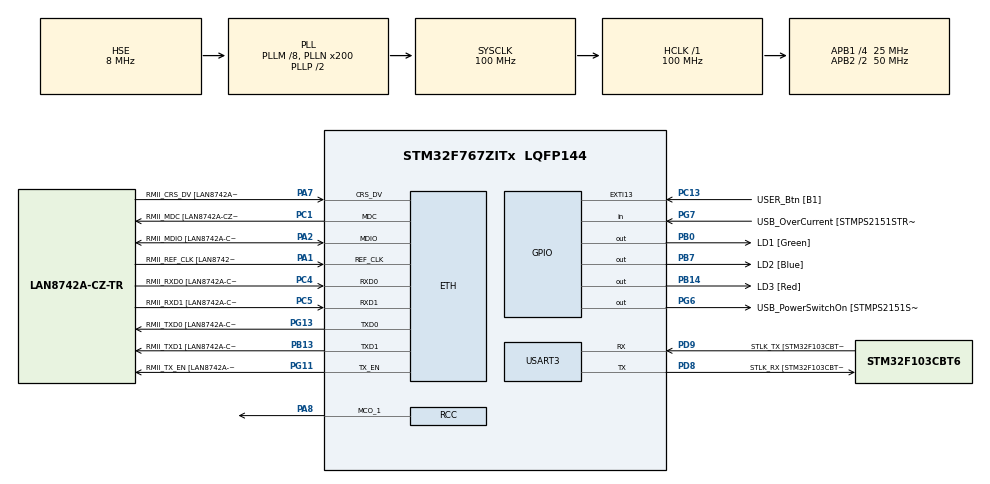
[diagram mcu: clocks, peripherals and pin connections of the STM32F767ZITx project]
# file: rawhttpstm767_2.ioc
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Mcu.Family=STM32F7
RCC.CortexFreq_Value=100000000
PG6.Signal=GPIO_Output
PB14.GPIO_Label=LD3 [Red]
PG6.GPIO_Label=USB_PowerSwitchOn [STMPS2151STR_EN]
PA14.GPIO_Label=TCK
RCC.SYSCLKSourceVirtual=RCC_SYSCLKSOURCE_PLLCLK
PB0.GPIO_Label=LD1 [Green]
PC14/OSC32_IN.Mode=LSE-External-Oscillator
PC5.Mode=RMII
PC13.GPIO_Label=USER_Btn [B1]
PB13.GPIO_Label=RMII_TXD1 [LAN8742A-CZ-TR_TXD1]
PB13.Signal=ETH_TXD1
PG13.Signal=ETH_TXD0
PD9.Mode=Asynchronous
PG11.Signal=ETH_TX_EN
RCC.SYSCLKSource=RCC_SYSCLKSOURCE_PLLCLK
ProjectManager.StackSize=0x400
LWIP.NETMASK_ADDRESS=255.255.000.000
LWIP.LWIP_HTTPD=1
USART3.VirtualMode-Asynchronous=VM_ASYNC
PA12.Signal=USB_OTG_FS_DP
ETH.PHY_Value=0
PH0/OSC_IN.Mode=HSE-External-Oscillator
RCC.HCLKFreq_Value=100000000
RCC.APB2TimFreq_Value=100000000
PH1/OSC_OUT.Signal=RCC_OSC_OUT
PD8.Signal=USART3_TX
RCC.AHBFreq_Value=100000000
RCC.HSE_VALUE=8000000
RCC.PLLMUL=RCC_PLL_MUL9
RCC.RCC_MCO1Source=RCC_MCO1SOURCE_PLLCLK
PC4.GPIO_Label=RMII_RXD0 [LAN8742A-CZ-TR_RXD0]
PA14.Mode=Serial_Wire
PA10.GPIO_Label=USB_ID
RCC.RCC_MCODiv1=RCC_MCODIV_4
PB7.Signal=GPIO_Output
PA8.Signal=RCC_MCO_1
PG13.Mode=RMII
ETH.PHY_Name=LAN8742A_PHY_ADDRESS
PH1/OSC_OUT.Mode=HSE-External-Oscillator
PB7.GPIO_Label=LD2 [Blue]
Mcu.Package=LQFP144
PC14/OSC32_IN.Signal=RCC_OSC32_IN
PA2.GPIO_Label=RMII_MDIO [LAN8742A-CZ-TR_MDIO]
PA10.Signal=USB_OTG_FS_ID
RCC.APB2CLKDivider=RCC_HCLK_DIV2
RCC.APB1TimFreq_Value=50000000
PG11.GPIO_Label=RMII_TX_EN [LAN8742A-CZ-TR_TXEN]
PC5.Signal=ETH_RXD1
PB13.Mode=RMII
PC4.Mode=RMII
LWIP.IP_ADDRESS=169.254.215.173
PB3.GPIO_Label=SWO
RCC.PLLSourceVirtual=RCC_PLLSOURCE_HSE
CORTEX_M7.CPU_ICache=Enabled
PA7.Mode=RMII
PG7.Signal=GPIO_Input
PD9.GPIO_Label=STLK_TX [STM32F103CBT6_PA2]
PC13.Signal=GPXTI13
PA9.GPIO_Label=USB_VBUS
PC4.Signal=ETH_RXD0
ETH.MACAddr=00\:80\:E1\:00\:00\:22
PA11.GPIO_Label=USB_DM
PD9.Signal=USART3_RX
LWIP.LWIP_DHCP=0
RCC.APB1CLKDivider=RCC_HCLK_DIV4
PG13.GPIO_Label=RMII_TXD0 [LAN8742A-CZ-TR_TXD0]
ETH.PhyAddress=0
PA12.GPIO_Label=USB_DP
VP_LWIP_VS_Enabled.Mode=Enabled
PD8.GPIO_Label=STLK_RX [STM32F103CBT6_PA3]
PA13.Signal=SYS_JTMS-SWDIO
CORTEX_M7.MPU_Control=MPU_HFNMI_PRIVDEF
ProjectManager.TargetToolchain=TrueSTUDIO
PA9.Signal=USB_OTG_FS_VBUS
RCC.USBFreq_Value=25000000
PD8.Mode=Asynchronous
PA1.Signal=ETH_REF_CLK
PB14.Signal=GPIO_Output
board=NUCLEO-F767ZI
RCC.VCOOutputFreq_Value=200000000
PH0/OSC_IN.Signal=RCC_OSC_IN
RCC.APB2Freq_Value=50000000
PA1.Mode=RMII
RCC.PRESCALERUSB=RCC_USBCLKSOURCE_PLL_DIV1_5
PG7.GPIO_Label=USB_OverCurrent [STMPS2151STR_FAULT]
PA1.GPIO_Label=RMII_REF_CLK [LAN8742A-CZ-TR_REFCLK0]
PC1.GPIO_Label=RMII_MDC [LAN8742A-CZ-TR_MDC]
PA13.Mode=Serial_Wire
Mcu.Name=STM32F767ZITx
PA2.Signal=ETH_MDIO
PA13.GPIO_Label=TMS
RCC.48MHZClocksFreq_Value=24000000
PB3.Signal=SYS_JTDO-SWO
RCC.SYSCLKFreq_VALUE=100000000
ETH.MediaInterface=ETH_MEDIA_INTERFACE_RMII
PA7.GPIO_Label=RMII_CRS_DV [LAN8742A-CZ-TR_CRS_DV]
PC5.GPIO_Label=RMII_RXD1 [LAN8742A-CZ-TR_RXD1]
PC15/OSC32_OUT.Mode=LSE-External-Oscillator
PG11.Mode=RMII
PA11.Signal=USB_OTG_FS_DM
PA14.Signal=SYS_JTCK-SWCLK
ProjectManager.HeapSize=0x200
LWIP.Version=v2.1.2_Cube
RCC.HSI_VALUE=16000000
PH0/OSC_IN.GPIO_Label=MCO [STM32F103CBT6_PA8]
RCC.PLLQ=8
NVIC.PriorityGroup=NVIC_PRIORITYGROUP_4
RCC.PLLM=8
RCC.PLLN=200
PA2.Mode=RMII
PC15/OSC32_OUT.Signal=RCC_OSC32_OUT
PA8.Mode=Clock-out-1
CORTEX_M7.CPU_DCache=Enabled
RCC.APB1Freq_Value=25000000
PB0.Signal=GPIO_Output
PC1.Signal=ETH_MDC
PC1.Mode=RMII
PA7.Signal=ETH_CRS_DV

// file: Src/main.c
/* USER CODE BEGIN Header */
/**
  ******************************************************************************
  * @file           : main.c
  * @brief          : Main program body
  ******************************************************************************
  * @attention
  *
  * <h2><center>&copy; Copyright (c) 2021 STMicroelectronics.
  * All rights reserved.</center></h2>
  *
  * This software component is licensed by ST under Ultimate Liberty license
  * SLA0044, the "License"; You may not use this file except in compliance with
  * the License. You may obtain a copy of the License at:
  *                             www.st.com/SLA0044
  *
  ******************************************************************************
  */
/* USER CODE END Header */

#include "main.h"
#include "lwip.h"

UART_HandleTypeDef huart3;

void SystemClock_Config(void);
static void MPU_Config(void);
static void MX_GPIO_Init(void);
static void MX_USART3_UART_Init(void);

int main(void)
{

  /* MPU Configuration--------------------------------------------------------*/
  MPU_Config();

  /* Enable I-Cache---------------------------------------------------------*/
  SCB_EnableICache();

  /* Enable D-Cache---------------------------------------------------------*/
  SCB_EnableDCache();

  /* MCU Configuration--------------------------------------------------------*/

  /* Reset of all peripherals, Initializes the Flash interface and the Systick. */
  HAL_Init();

  /* Configure the system clock */
  SystemClock_Config();

  /* Initialize all configured peripherals */
  MX_GPIO_Init();
  MX_USART3_UART_Init();
  MX_LWIP_Init();
  /* USER CODE BEGIN 2 */
  httpd_init();

  /* USER CODE END 2 */

  /* Infinite loop */
  /* USER CODE BEGIN WHILE */
  while (1)
  {
	  MX_LWIP_Process();
	  HAL_Delay(1);
    /* USER CODE END WHILE */

  }
}

void SystemClock_Config(void)
{
  RCC_OscInitTypeDef RCC_OscInitStruct = {0};
  RCC_ClkInitTypeDef RCC_ClkInitStruct = {0};
  RCC_PeriphCLKInitTypeDef PeriphClkInitStruct = {0};

  /** Configure LSE Drive Capability
  */
  HAL_PWR_EnableBkUpAccess();
  /** Configure the main internal regulator output voltage
  */
  __HAL_RCC_PWR_CLK_ENABLE();
  __HAL_PWR_VOLTAGESCALING_CONFIG(PWR_REGULATOR_VOLTAGE_SCALE3);
  /** Initializes the CPU, AHB and APB busses clocks
  */
  RCC_OscInitStruct.OscillatorType = RCC_OSCILLATORTYPE_HSE;
  RCC_OscInitStruct.HSEState = RCC_HSE_ON;
  RCC_OscInitStruct.PLL.PLLState = RCC_PLL_ON;
  RCC_OscInitStruct.PLL.PLLSource = RCC_PLLSOURCE_HSE;
  RCC_OscInitStruct.PLL.PLLM = 8;
  RCC_OscInitStruct.PLL.PLLN = 200;
  RCC_OscInitStruct.PLL.PLLP = RCC_PLLP_DIV2;
  RCC_OscInitStruct.PLL.PLLQ = 8;
  if (HAL_RCC_OscConfig(&RCC_OscInitStruct) != HAL_OK)
  {
    Error_Handler();
  }
  /** Initializes the CPU, AHB and APB busses clocks
  */
  RCC_ClkInitStruct.ClockType = RCC_CLOCKTYPE_HCLK|RCC_CLOCKTYPE_SYSCLK
                              |RCC_CLOCKTYPE_PCLK1|RCC_CLOCKTYPE_PCLK2;
  RCC_ClkInitStruct.SYSCLKSource = RCC_SYSCLKSOURCE_PLLCLK;
  RCC_ClkInitStruct.AHBCLKDivider = RCC_SYSCLK_DIV1;
  RCC_ClkInitStruct.APB1CLKDivider = RCC_HCLK_DIV4;
  RCC_ClkInitStruct.APB2CLKDivider = RCC_HCLK_DIV2;

  if (HAL_RCC_ClockConfig(&RCC_ClkInitStruct, FLASH_LATENCY_3) != HAL_OK)
  {
    Error_Handler();
  }
  PeriphClkInitStruct.PeriphClockSelection = RCC_PERIPHCLK_USART3;
  PeriphClkInitStruct.Usart3ClockSelection = RCC_USART3CLKSOURCE_PCLK1;
  if (HAL_RCCEx_PeriphCLKConfig(&PeriphClkInitStruct) != HAL_OK)
  {
    Error_Handler();
  }
  HAL_RCC_MCOConfig(RCC_MCO1, RCC_MCO1SOURCE_PLLCLK, RCC_MCODIV_4);
}

static void MX_USART3_UART_Init(void)
{

  huart3.Instance = USART3;
  huart3.Init.BaudRate = 115200;
  huart3.Init.WordLength = UART_WORDLENGTH_8B;
  huart3.Init.StopBits = UART_STOPBITS_1;
  huart3.Init.Parity = UART_PARITY_NONE;
  huart3.Init.Mode = UART_MODE_TX_RX;
  huart3.Init.HwFlowCtl = UART_HWCONTROL_NONE;
  huart3.Init.OverSampling = UART_OVERSAMPLING_16;
  huart3.Init.OneBitSampling = UART_ONE_BIT_SAMPLE_DISABLE;
  huart3.AdvancedInit.AdvFeatureInit = UART_ADVFEATURE_NO_INIT;
  if (HAL_UART_Init(&huart3) != HAL_OK)
  {
    Error_Handler();
  }

}

static void MX_GPIO_Init(void)
{
  GPIO_InitTypeDef GPIO_InitStruct = {0};

  /* GPIO Ports Clock Enable */
  __HAL_RCC_GPIOC_CLK_ENABLE();
  __HAL_RCC_GPIOH_CLK_ENABLE();
  __HAL_RCC_GPIOA_CLK_ENABLE();
  __HAL_RCC_GPIOB_CLK_ENABLE();
  __HAL_RCC_GPIOD_CLK_ENABLE();
  __HAL_RCC_GPIOG_CLK_ENABLE();

  /*Configure GPIO pin Output Level */
  HAL_GPIO_WritePin(GPIOB, LD1_Pin|LD3_Pin|LD2_Pin, GPIO_PIN_RESET);

  /*Configure GPIO pin Output Level */
  HAL_GPIO_WritePin(USB_PowerSwitchOn_GPIO_Port, USB_PowerSwitchOn_Pin, GPIO_PIN_RESET);

  /*Configure GPIO pin : USER_Btn_Pin */
  GPIO_InitStruct.Pin = USER_Btn_Pin;
  GPIO_InitStruct.Mode = GPIO_MODE_IT_RISING;
  GPIO_InitStruct.Pull = GPIO_NOPULL;
  HAL_GPIO_Init(USER_Btn_GPIO_Port, &GPIO_InitStruct);

  /*Configure GPIO pins : LD1_Pin LD3_Pin LD2_Pin */
  GPIO_InitStruct.Pin = LD1_Pin|LD3_Pin|LD2_Pin;
  GPIO_InitStruct.Mode = GPIO_MODE_OUTPUT_PP;
  GPIO_InitStruct.Pull = GPIO_NOPULL;
  GPIO_InitStruct.Speed = GPIO_SPEED_FREQ_LOW;
  HAL_GPIO_Init(GPIOB, &GPIO_InitStruct);

  /*Configure GPIO pin : USB_PowerSwitchOn_Pin */
  GPIO_InitStruct.Pin = USB_PowerSwitchOn_Pin;
  GPIO_InitStruct.Mode = GPIO_MODE_OUTPUT_PP;
  GPIO_InitStruct.Pull = GPIO_NOPULL;
  GPIO_InitStruct.Speed = GPIO_SPEED_FREQ_LOW;
  HAL_GPIO_Init(USB_PowerSwitchOn_GPIO_Port, &GPIO_InitStruct);

  /*Configure GPIO pin : USB_OverCurrent_Pin */
  GPIO_InitStruct.Pin = USB_OverCurrent_Pin;
  GPIO_InitStruct.Mode = GPIO_MODE_INPUT;
  GPIO_InitStruct.Pull = GPIO_NOPULL;
  HAL_GPIO_Init(USB_OverCurrent_GPIO_Port, &GPIO_InitStruct);

  /*Configure GPIO pin : PA8 */
  GPIO_InitStruct.Pin = GPIO_PIN_8;
  GPIO_InitStruct.Mode = GPIO_MODE_AF_PP;
  GPIO_InitStruct.Pull = GPIO_NOPULL;
  GPIO_InitStruct.Speed = GPIO_SPEED_FREQ_LOW;
  GPIO_InitStruct.Alternate = GPIO_AF0_MCO;
  HAL_GPIO_Init(GPIOA, &GPIO_InitStruct);

  /*Configure GPIO pin : USB_VBUS_Pin */
  GPIO_InitStruct.Pin = USB_VBUS_Pin;
  GPIO_InitStruct.Mode = GPIO_MODE_INPUT;
  GPIO_InitStruct.Pull = GPIO_NOPULL;
  HAL_GPIO_Init(USB_VBUS_GPIO_Port, &GPIO_InitStruct);

  /*Configure GPIO pins : USB_ID_Pin USB_DM_Pin USB_DP_Pin */
  GPIO_InitStruct.Pin = USB_ID_Pin|USB_DM_Pin|USB_DP_Pin;
  GPIO_InitStruct.Mode = GPIO_MODE_AF_PP;
  GPIO_InitStruct.Pull = GPIO_NOPULL;
  GPIO_InitStruct.Speed = GPIO_SPEED_FREQ_VERY_HIGH;
  GPIO_InitStruct.Alternate = GPIO_AF10_OTG_FS;
  HAL_GPIO_Init(GPIOA, &GPIO_InitStruct);

}

/* MPU Configuration */

void MPU_Config(void)
{

  /* Disables the MPU */
	/* Disables the MPU */
		  MPU_Region_InitTypeDef MPU_InitStruct;

		  /* Disable the MPU */
		  HAL_MPU_Disable();

		  /* Configure the MPU as Normal Non Cacheable for Ethernet Buffers in the SRAM2 */
		  MPU_InitStruct.Enable = MPU_REGION_ENABLE;
		  MPU_InitStruct.BaseAddress = 0x2007C000;
		  MPU_InitStruct.Size = MPU_REGION_SIZE_16KB;
		  MPU_InitStruct.AccessPermission = MPU_REGION_FULL_ACCESS;
		  MPU_InitStruct.IsBufferable = MPU_ACCESS_NOT_BUFFERABLE;
		  MPU_InitStruct.IsCacheable = MPU_ACCESS_NOT_CACHEABLE;
		  MPU_InitStruct.IsShareable = MPU_ACCESS_SHAREABLE;
		  MPU_InitStruct.Number = MPU_REGION_NUMBER0;
		  MPU_InitStruct.TypeExtField = MPU_TEX_LEVEL1;
		  MPU_InitStruct.SubRegionDisable = 0x00;
		  MPU_InitStruct.DisableExec = MPU_INSTRUCTION_ACCESS_ENABLE;

		  HAL_MPU_ConfigRegion(&MPU_InitStruct);

		  /* Configure the MPU as Device for Ethernet Descriptors in the SRAM2 */
		  MPU_InitStruct.Enable = MPU_REGION_ENABLE;
		  MPU_InitStruct.BaseAddress = 0x2007C000;
		  MPU_InitStruct.Size = MPU_REGION_SIZE_256B;
		  MPU_InitStruct.AccessPermission = MPU_REGION_FULL_ACCESS;
		  MPU_InitStruct.IsBufferable = MPU_ACCESS_BUFFERABLE;
		  MPU_InitStruct.IsCacheable = MPU_ACCESS_NOT_CACHEABLE;
		  MPU_InitStruct.IsShareable = MPU_ACCESS_SHAREABLE;
		  MPU_InitStruct.Number = MPU_REGION_NUMBER1;
		  MPU_InitStruct.TypeExtField = MPU_TEX_LEVEL0;
		  MPU_InitStruct.SubRegionDisable = 0x00;
		  MPU_InitStruct.DisableExec = MPU_INSTRUCTION_ACCESS_ENABLE;

		  HAL_MPU_ConfigRegion(&MPU_InitStruct);

		  /* Enable the MPU */
		  HAL_MPU_Enable(MPU_PRIVILEGED_DEFAULT);

}

void Error_Handler(void)
{
}

/************************ (C) COPYRIGHT STMicroelectronics *****END OF FILE****/
